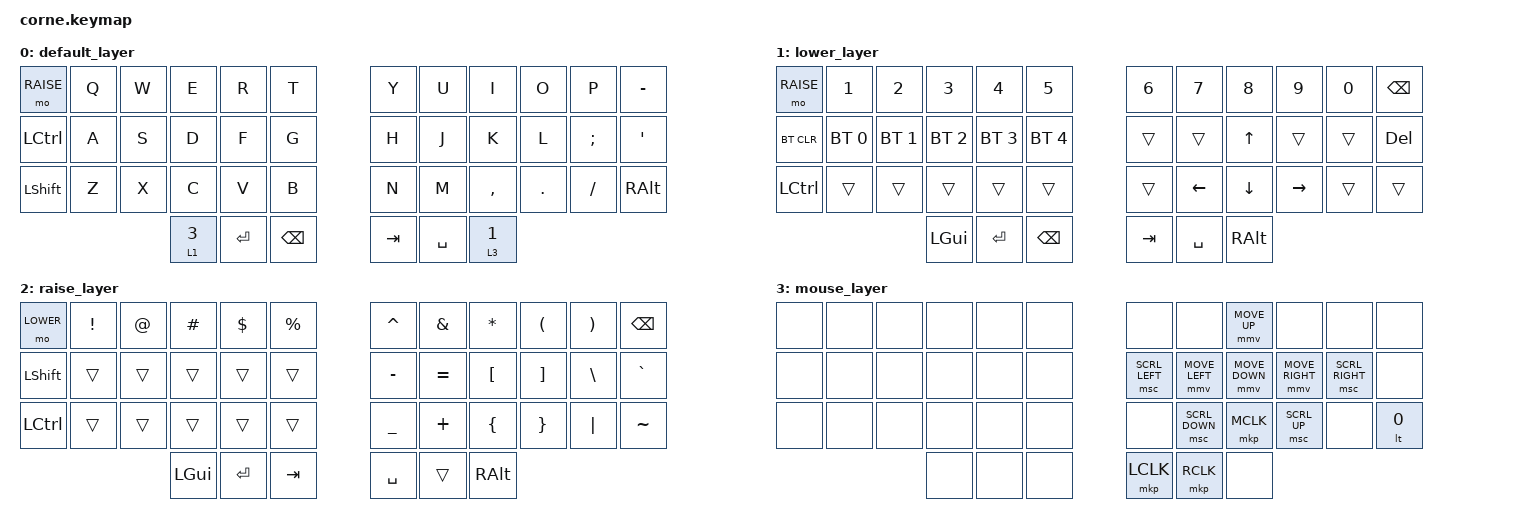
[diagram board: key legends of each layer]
/*
 * Copyright (c) 2020 The ZMK Contributors
 *
 * SPDX-License-Identifier: MIT
 */

#include <behaviors.dtsi>
#include <dt-bindings/zmk/keys.h>
#include <dt-bindings/zmk/bt.h>
#include <dt-bindings/zmk/pointing.h>

#define DEFAULT 0
#define LOWER   1
#define RAISE   2
#define MOUSE   3


/ {
    keymap {
        compatible = "zmk,keymap";

        default_layer {
            // -----------------------------------------------------------------------------------------
            // |  L2  |  Q  |  W  |  E  |  R  |  T  |       |  Y  |  U   |  I  |  O  |  P  |  -   |
            // | CTRL |  A  |  S  |  D  |  F  |  G  |       |  H  |  J   |  K  |  L  |  ;  |  '   |
            // | SHFT |  Z  |  X  |  C  |  V  |  B  |       |  N   |  M  |  ,  |  .  |  /  | MOUSE|
            //                    | LOWER   | RET | BSPC|       | TAB | SPACE| ALT |
            bindings = <
                &mo RAISE     &kp Q     &kp W     &kp E     &kp R     &kp T         &kp Y      &kp U     &kp I     &kp O     &kp P      &kp MINUS
                &kp LCTRL     &kp A     &kp S     &kp D     &kp F     &kp G         &kp H      &kp J     &kp K     &kp L     &kp SEMI   &kp SQT
                &kp LSHFT     &kp Z     &kp X     &kp C     &kp V     &kp B         &kp N      &kp M     &kp COMMA &kp DOT   &kp FSLH   &kp RALT
                              &lt 1 3      &kp RET   &kp BSPC                &kp TAB    &kp SPACE &lt 3 1 
            >;
        };

        lower_layer {
            // -----------------------------------------------------------------------------------------
            // |  L2  |  1  |  2  |  3  |  4  |  5  |       |  6  |  7  |  8  |  9  |  0  | BSPC |
            // | BTCLR| BT1 | BT2 | BT3 | BT4 | BT5 |       |     |     | UP  |     |     | DEL  |
            // | LCTRL|     |     |     |     |     |       |     |LEFT |DOWN |RIGHT|     |      |
            //                    | GUI | RET | BSPC |       | TAB | SPACE| ALT |
            bindings = <
                &mo RAISE  &kp N1       &kp N2       &kp N3       &kp N4       &kp N5        &kp N6      &kp N7      &kp N8      &kp N9      &kp N0      &kp BSPC
                &bt BT_CLR &bt BT_SEL 0 &bt BT_SEL 1 &bt BT_SEL 2 &bt BT_SEL 3 &bt BT_SEL 4  &trans      &trans      &kp UP      &trans      &trans      &kp DEL
                &kp LCTRL  &trans       &trans       &trans       &trans       &trans        &trans      &kp LEFT    &kp DOWN    &kp RIGHT   &trans      &trans
                              &kp LGUI     &kp RET     &kp BSPC                 &kp TAB    &kp SPACE &kp RALT
            >;
        };

        raise_layer {
            // -----------------------------------------------------------------------------------------
            // |  L2  |  !  |  @  |  #  |  $  |  %  |       |  ^  |  &  |  *  |  (  |  )  | BSPC |
            // | CTRL |     |     |     |     |     |       |  -  |  =  |  [  |  ]  |  \  |  `   |
            // | LCTRL|     |     |     |     |     |       |  _  |  +  |  {  |  }  | "|" |  ~   |
            //                    | GUI | RET | TAB |       | SPC |     | ALT |
            bindings = <
                &mo LOWER   &kp EXCL &kp AT &kp HASH &kp DLLR &kp PRCNT   &kp CARET &kp AMPS  &kp ASTRK &kp LPAR &kp RPAR &kp BSPC
                &kp LSHFT   &trans   &trans &trans   &trans   &trans      &kp MINUS &kp EQUAL &kp LBKT  &kp RBKT &kp BSLH &kp GRAVE
                &kp LCTRL   &trans   &trans &trans   &trans   &trans      &kp UNDER &kp PLUS  &kp LBRC  &kp RBRC &kp PIPE &kp TILDE
                              &kp LGUI     &kp RET  &kp TAB                &kp SPACE &trans    &kp RALT
            >;
        };
        mouse_layer {
            // -----------------------------------------------------------------------------------------
            // |       |       |       |       |       |       |     |    | LCLK |  UP  | RCLK |       |       |
            // |       |       |       |       |       |       |     |    |  SCRL_Left | LEFT  | DOWN | RIGHT|  SCRL_RIGHT |       |
            // |       |       |       |       |       |       |     |    |       | S-DWN | MMB  | S-UP |       |  DEFAULT     |
            //                    |       |       |       |       |       |       |
            bindings = <
                &none    &none    &none    &none    &none    &none          &none   &none   &mmv MOVE_UP  &none  &none    &none
                &none    &none    &none    &none    &none    &none          &msc SCRL_LEFT   &mmv MOVE_LEFT &mmv MOVE_DOWN &mmv MOVE_RIGHT &msc SCRL_RIGHT   &none
                &none    &none    &none    &none    &none    &none          &none    &msc SCRL_DOWN &mkp MCLK    &msc SCRL_UP  &none    &lt 0
                                &none    &none    &none                     &mkp LCLK    &mkp RCLK      &none
            >;
        };
    };
};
